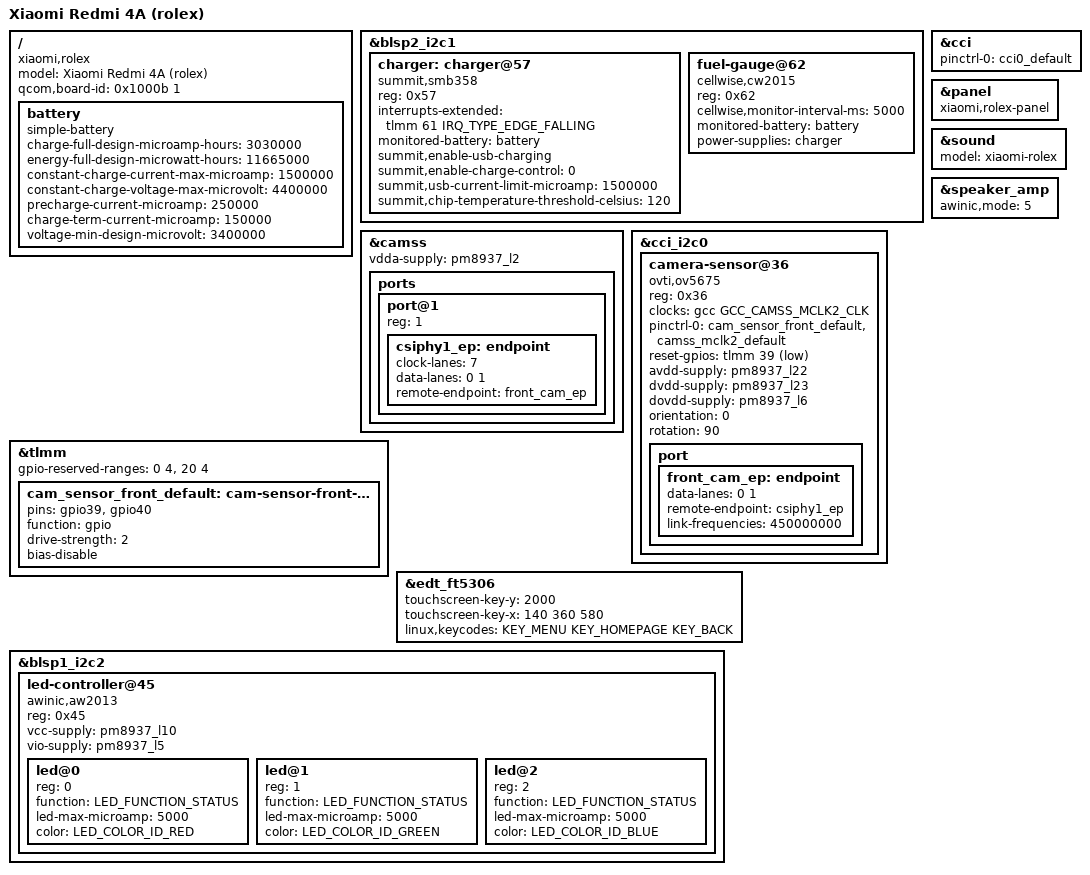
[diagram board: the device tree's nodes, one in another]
// SPDX-License-Identifier: GPL-2.0-only
/*
 * Copyright (c) 2026, Barnabas Czeman
 */

/dts-v1/;

#include <dt-bindings/leds/common.h>
#include "msm8917-xiaomi-wingtech.dtsi"

/ {
	model = "Xiaomi Redmi 4A (rolex)";
	compatible = "xiaomi,rolex", "qcom,msm8917";

	qcom,board-id = <0x1000b 1>;

	battery: battery {
		compatible = "simple-battery";
		charge-full-design-microamp-hours = <3030000>;
		energy-full-design-microwatt-hours = <11665000>;
		constant-charge-current-max-microamp = <1500000>;
		constant-charge-voltage-max-microvolt = <4400000>;
		precharge-current-microamp = <250000>;
		charge-term-current-microamp = <150000>;
		voltage-min-design-microvolt = <3400000>;
	};
};

&blsp2_i2c1 {
	status = "okay";

	charger: charger@57 {
		compatible = "summit,smb358";
		reg = <0x57>;

		interrupts-extended = <&tlmm 61 IRQ_TYPE_EDGE_FALLING>;

		monitored-battery = <&battery>;

		summit,enable-usb-charging;
		summit,enable-charge-control = <0>;
		summit,usb-current-limit-microamp = <1500000>;
		summit,chip-temperature-threshold-celsius = <120>;
	};

	fuel-gauge@62 {
		compatible = "cellwise,cw2015";
		reg = <0x62>;

		cellwise,monitor-interval-ms = <5000>;

		monitored-battery = <&battery>;
		power-supplies = <&charger>;
	};
};

&camss {
	vdda-supply = <&pm8937_l2>;
	status = "okay";

	ports {
		port@1 {
			reg = <1>;

			csiphy1_ep: endpoint {
				clock-lanes = <7>;
				data-lanes = <0 1>;
				remote-endpoint = <&front_cam_ep>;
			};
		};
	};
};

&cci {
	pinctrl-0 = <&cci0_default>;
	pinctrl-names = "default";

	status = "okay";
};

&cci_i2c0 {
	camera-sensor@36 {
		compatible = "ovti,ov5675";

		reg = <0x36>;

		clocks = <&gcc GCC_CAMSS_MCLK2_CLK>;

		pinctrl-0 = <&cam_sensor_front_default>, <&camss_mclk2_default>;
		pinctrl-names = "default";

		reset-gpios = <&tlmm 39 GPIO_ACTIVE_LOW>;

		avdd-supply= <&pm8937_l22>;
		dvdd-supply = <&pm8937_l23>;
		dovdd-supply = <&pm8937_l6>;
		orientation = <0>;
		rotation = <90>;

		port {
			front_cam_ep: endpoint {
				data-lanes = <0 1>;
				remote-endpoint = <&csiphy1_ep>;
				link-frequencies = /bits/ 64 <450000000>;
			};
		};
	};
};

&panel {
	compatible = "xiaomi,rolex-panel";
};

&sound {
	model = "xiaomi-rolex";
};

&speaker_amp {
	awinic,mode = <5>;

	status = "okay";
};

&tlmm {
	gpio-reserved-ranges = <0 4>, <20 4>;

	cam_sensor_front_default: cam-sensor-front-default-state {
		pins = "gpio39", "gpio40";
		function = "gpio";
		drive-strength = <2>;
		bias-disable;
	};
};

&edt_ft5306 {
	status = "okay";

	/*
	 * The capacitive keys are part of the touch panel and are reported as
	 * touches at y = 2000, well outside the 720x1280 display area. The
	 * values come from the downstream device tree, which describes them
	 * as ftech,virtual-key<n> = <keycode x y>.
	 */
	touchscreen-key-y = <2000>;
	touchscreen-key-x = <140 360 580>;
	linux,keycodes = <KEY_MENU KEY_HOMEPAGE KEY_BACK>;
};

/delete-node/ &goodix_gt911;

&blsp1_i2c2 {
	/*
	 * RGB notification LED, on the same bus as the LCD bias regulator.
	 * Downstream describes it as aw2013@45 with red, green and blue
	 * channels and rgb_led-supply = <&pm8917_l10>.
	 */
	led-controller@45 {
		compatible = "awinic,aw2013";
		reg = <0x45>;
		#address-cells = <1>;
		#size-cells = <0>;

		vcc-supply = <&pm8937_l10>;
		vio-supply = <&pm8937_l5>;

		led@0 {
			reg = <0>;
			function = LED_FUNCTION_STATUS;
			led-max-microamp = <5000>;
			color = <LED_COLOR_ID_RED>;
		};

		led@1 {
			reg = <1>;
			function = LED_FUNCTION_STATUS;
			led-max-microamp = <5000>;
			color = <LED_COLOR_ID_GREEN>;
		};

		led@2 {
			reg = <2>;
			function = LED_FUNCTION_STATUS;
			led-max-microamp = <5000>;
			color = <LED_COLOR_ID_BLUE>;
		};
	};
};
